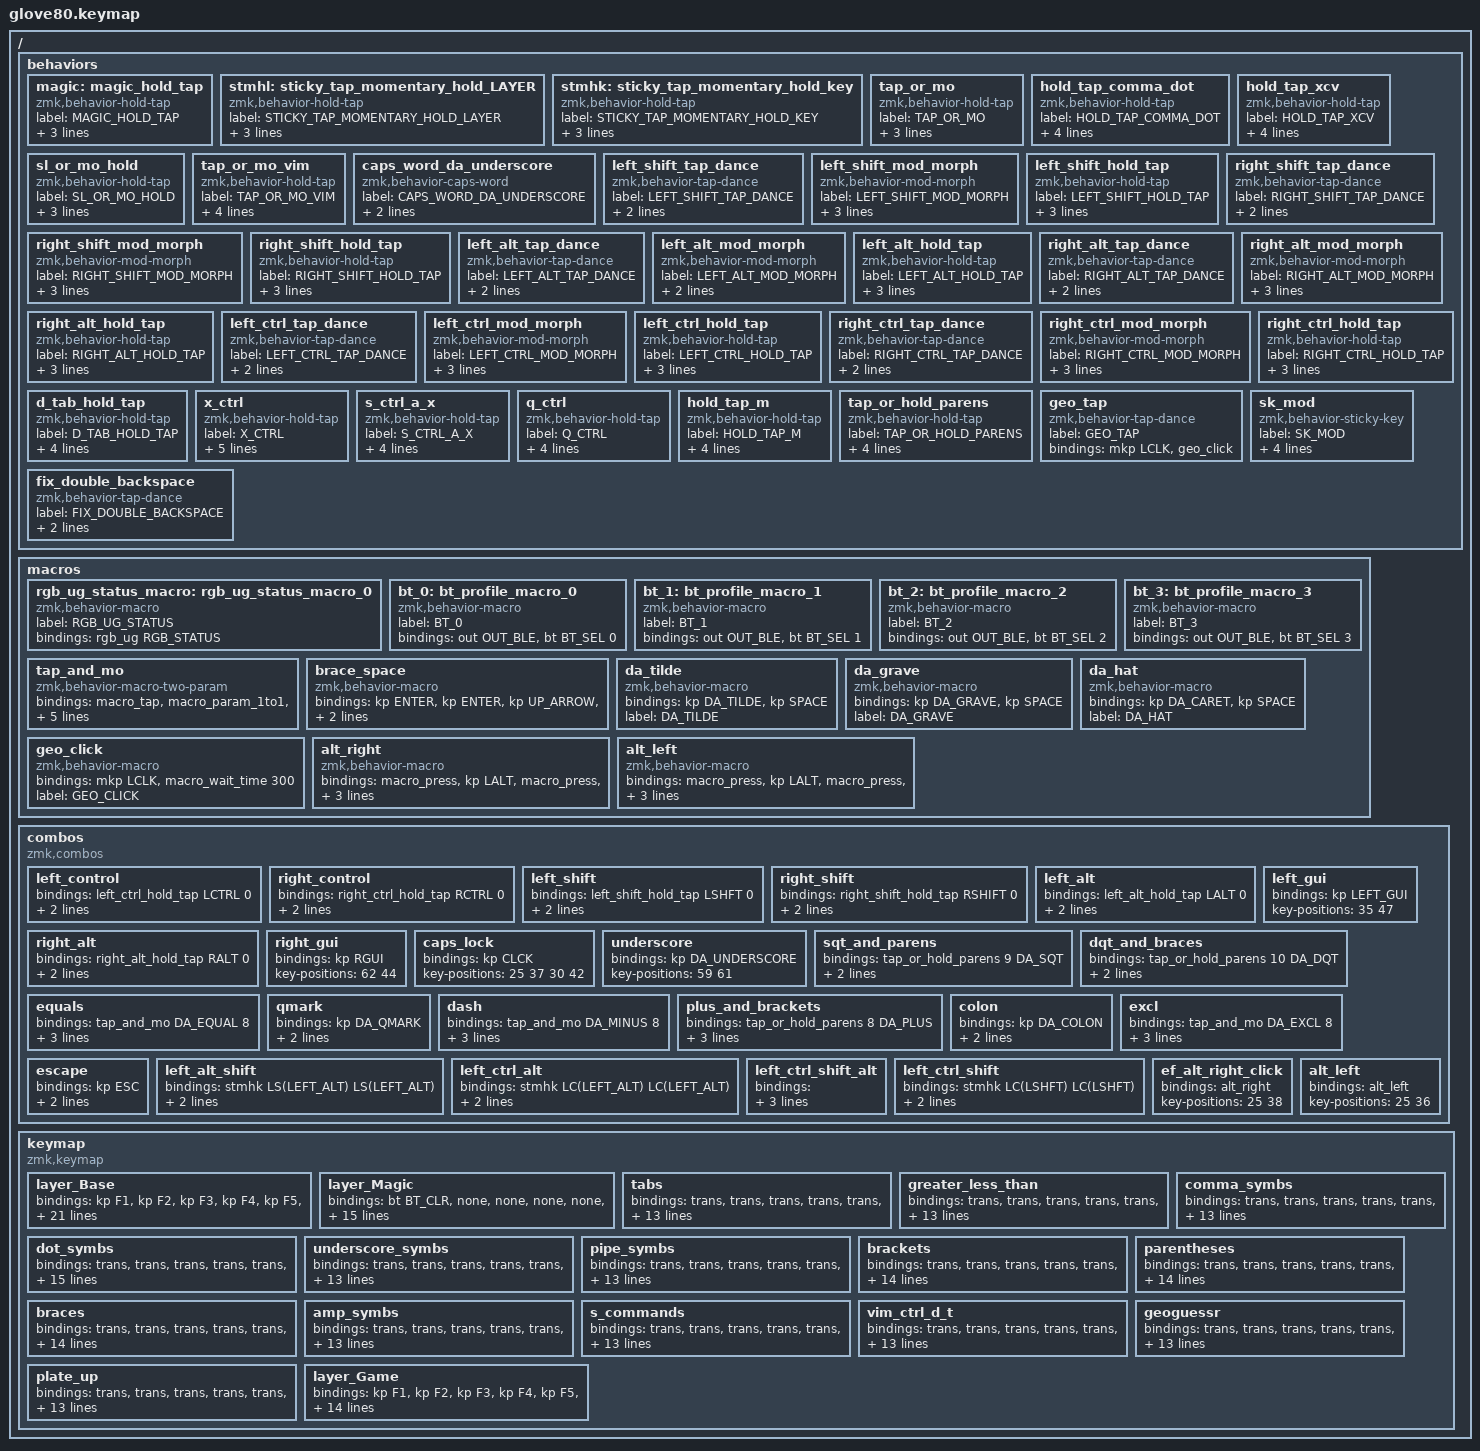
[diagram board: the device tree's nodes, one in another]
/*
 * Copyright (c) 2020 The ZMK Contributors
 * Copyright (c) 2022 Innaworks Development Limited, trading as MoErgo
 *
 * SPDX-License-Identifier: MIT
 */
/* THIS FILE WAS GENERATED BY GLOVE80 LAYOUT EDITOR
 *
 * This file was generated automatically. You may or may not want to
 * edit it directly.
 */
/* Include all behaviour includes needed by system behaviors/macros */
/* Include behaviour includes needed by key binds - automatically generated */

#include "keys_da.h"
#include <dt-bindings/zmk/mouse.h>
#include <behaviors.dtsi>
#include <dt-bindings/zmk/bt.h>
#include <dt-bindings/zmk/keys.h>
#include <dt-bindings/zmk/outputs.h>
//#include <dt-bindings/zmk/pointing.h>
#include <dt-bindings/zmk/rgb.h>

/ {
    /* Glove80 system behavior & macros */

    behaviors {
        // For the "layer" key, it'd nice to be able to use it as either a shift or a toggle.
        // Configure it as a tap dance, so the first tap (or hold) is a &mo and the second tap is a &to

        magic: magic_hold_tap {
            compatible = "zmk,behavior-hold-tap";
            label = "MAGIC_HOLD_TAP";
            #binding-cells = <2>;
            flavor = "tap-preferred";
            tapping-term-ms = <200>;
            bindings = <&mo>, <&rgb_ug_status_macro>;
        };

        stmhl: sticky_tap_momentary_hold_LAYER {
            compatible = "zmk,behavior-hold-tap";
            label = "STICKY_TAP_MOMENTARY_HOLD_LAYER";
            bindings = <&mo>, <&sl>;

            #binding-cells = <2>;
            tapping-term-ms = <400>;
            flavor = "tap-preferred";
        };

        stmhk: sticky_tap_momentary_hold_key {
            compatible = "zmk,behavior-hold-tap";
            label = "STICKY_TAP_MOMENTARY_HOLD_KEY";
            bindings = <&kp>, <&sk>;

            #binding-cells = <2>;
            tapping-term-ms = <400>;
            flavor = "hold-preferred";
        };

        tap_or_mo: tap_or_mo {
            compatible = "zmk,behavior-hold-tap";
            label = "TAP_OR_MO";
            bindings = <&mo>, <&kp>;

            #binding-cells = <2>;
            flavor = "hold-preferred";
            tapping-term-ms = <300>;
        };

        hold_tap_comma_dot: hold_tap_comma_dot {
            compatible = "zmk,behavior-hold-tap";
            label = "HOLD_TAP_COMMA_DOT";
            bindings = <&mo>, <&kp>;

            #binding-cells = <2>;
            flavor = "hold-preferred";
            tapping-term-ms = <300>;
            hold-trigger-key-positions = <61 60 42 30 59>;
        };

        hold_tap_xcv: hold_tap_xcv {
            compatible = "zmk,behavior-hold-tap";
            label = "HOLD_TAP_XCV";
            bindings = <&mo>, <&kp>;

            #binding-cells = <2>;
            flavor = "hold-preferred";
            tapping-term-ms = <300>;
            hold-trigger-key-positions = <48 50>;
        };

        sl_or_mo_hold: sl_or_mo_hold {
            compatible = "zmk,behavior-hold-tap";
            label = "SL_OR_MO_HOLD";
            bindings = <&mo>, <&sl>;

            #binding-cells = <2>;
            flavor = "hold-preferred";
            tapping-term-ms = <300>;
        };

        tap_or_mo_vim: tap_or_mo_vim {
            compatible = "zmk,behavior-hold-tap";
            label = "TAP_OR_MO_VIM";
            bindings = <&mo>, <&kp>;

            #binding-cells = <2>;
            flavor = "hold-preferred";
            tapping-term-ms = <300>;
            hold-trigger-key-positions = <36 37 38 25>;
        };

        caps_word_da_underscore: caps_word_da_underscore {
            compatible = "zmk,behavior-caps-word";
            label = "CAPS_WORD_DA_UNDERSCORE";
            #binding-cells = <0>;
            continue-list = <DA_UNDERSCORE DA_MINUS>;
            mods = <(MOD_LSFT)>;
        };

        left_shift_tap_dance: left_shift_tap_dance {
            compatible = "zmk,behavior-tap-dance";
            label = "LEFT_SHIFT_TAP_DANCE";
            #binding-cells = <0>;
            bindings = <&sk LSHFT>, <&kp LC(DA_H)>;

            tapping-term-ms = <400>;
        };

        left_shift_mod_morph: left_shift_mod_morph {
            compatible = "zmk,behavior-mod-morph";
            label = "LEFT_SHIFT_MOD_MORPH";
            bindings = <&left_shift_tap_dance>, <&caps_word_da_underscore>;

            #binding-cells = <0>;
            mods = <(MOD_RSFT)>;
        };

        left_shift_hold_tap: left_shift_hold_tap {
            compatible = "zmk,behavior-hold-tap";
            label = "LEFT_SHIFT_HOLD_TAP";
            bindings = <&kp>, <&left_shift_mod_morph>;

            #binding-cells = <2>;
            tapping-term-ms = <400>;
            quick-tap-ms = <400>;
        };

        right_shift_tap_dance: right_shift_tap_dance {
            compatible = "zmk,behavior-tap-dance";
            label = "RIGHT_SHIFT_TAP_DANCE";
            #binding-cells = <0>;
            bindings = <&sk RSHFT>, <&kp RC(DA_K)>;

            tapping-term-ms = <400>;
        };

        right_shift_mod_morph: right_shift_mod_morph {
            compatible = "zmk,behavior-mod-morph";
            label = "RIGHT_SHIFT_MOD_MORPH";
            bindings = <&right_shift_tap_dance>, <&caps_word_da_underscore>;

            #binding-cells = <0>;
            mods = <(MOD_LSFT)>;
        };

        right_shift_hold_tap: right_shift_hold_tap {
            compatible = "zmk,behavior-hold-tap";
            label = "RIGHT_SHIFT_HOLD_TAP";
            bindings = <&kp>, <&right_shift_mod_morph>;

            #binding-cells = <2>;
            tapping-term-ms = <400>;
            quick-tap-ms = <400>;
        };

        left_alt_tap_dance: left_alt_tap_dance {
            compatible = "zmk,behavior-tap-dance";
            label = "LEFT_ALT_TAP_DANCE";
            #binding-cells = <0>;
            bindings = <&sk LALT>, <&kp LEFT_ALT>;

            tapping-term-ms = <400>;
        };

        left_alt_mod_morph: left_alt_mod_morph {
            compatible = "zmk,behavior-mod-morph";
            label = "LEFT_ALT_MOD_MORPH";
            bindings = <&left_alt_tap_dance>, <&kp LA(LS(ENTER))>;

            #binding-cells = <0>;
            mods = <(MOD_RALT)>;
        };

        left_alt_hold_tap: left_alt_hold_tap {
            compatible = "zmk,behavior-hold-tap";
            label = "LEFT_ALT_HOLD_TAP";
            bindings = <&kp>, <&left_alt_mod_morph>;

            #binding-cells = <2>;
            tapping-term-ms = <400>;
            quick-tap-ms = <400>;
        };

        right_alt_tap_dance: right_alt_tap_dance {
            compatible = "zmk,behavior-tap-dance";
            label = "RIGHT_ALT_TAP_DANCE";
            #binding-cells = <0>;
            bindings = <&sk RALT>, <&kp LA(P)>;

            tapping-term-ms = <400>;
        };

        right_alt_mod_morph: right_alt_mod_morph {
            compatible = "zmk,behavior-mod-morph";
            label = "RIGHT_ALT_MOD_MORPH";
            bindings = <&right_alt_tap_dance>, <&kp LA(LS(ENTER))>;

            #binding-cells = <0>;
            mods = <(MOD_LALT)>;
        };

        right_alt_hold_tap: right_alt_hold_tap {
            compatible = "zmk,behavior-hold-tap";
            label = "RIGHT_ALT_HOLD_TAP";
            bindings = <&kp>, <&right_alt_mod_morph>;

            #binding-cells = <2>;
            tapping-term-ms = <400>;
            quick-tap-ms = <400>;
        };

        left_ctrl_tap_dance: left_ctrl_tap_dance {
            compatible = "zmk,behavior-tap-dance";
            label = "LEFT_CTRL_TAP_DANCE";
            #binding-cells = <0>;
            bindings = <&sk LCTRL>, <&kp LCTRL>;

            tapping-term-ms = <400>;
        };

        left_ctrl_mod_morph: left_ctrl_mod_morph {
            compatible = "zmk,behavior-mod-morph";
            label = "LEFT_CTRL_MOD_MORPH";
            bindings = <&left_ctrl_tap_dance>, <&kp LA(LS(ENTER))>;

            #binding-cells = <0>;
            mods = <(MOD_RCTL)>;
        };

        left_ctrl_hold_tap: left_ctrl_hold_tap {
            compatible = "zmk,behavior-hold-tap";
            label = "LEFT_CTRL_HOLD_TAP";
            bindings = <&kp>, <&left_ctrl_mod_morph>;

            #binding-cells = <2>;
            tapping-term-ms = <400>;
            quick-tap-ms = <400>;
        };

        right_ctrl_tap_dance: right_ctrl_tap_dance {
            compatible = "zmk,behavior-tap-dance";
            label = "RIGHT_CTRL_TAP_DANCE";
            #binding-cells = <0>;
            bindings = <&sk RCTRL>, <&kp LA(P)>;

            tapping-term-ms = <400>;
        };

        right_ctrl_mod_morph: right_ctrl_mod_morph {
            compatible = "zmk,behavior-mod-morph";
            label = "RIGHT_CTRL_MOD_MORPH";
            bindings = <&right_ctrl_tap_dance>, <&kp LA(LS(ENTER))>;

            #binding-cells = <0>;
            mods = <(MOD_LCTL)>;
        };

        right_ctrl_hold_tap: right_ctrl_hold_tap {
            compatible = "zmk,behavior-hold-tap";
            label = "RIGHT_CTRL_HOLD_TAP";
            bindings = <&kp>, <&right_ctrl_mod_morph>;

            #binding-cells = <2>;
            tapping-term-ms = <400>;
            quick-tap-ms = <400>;
        };

        d_tab_hold_tap: d_tab_hold_tap {
            compatible = "zmk,behavior-hold-tap";
            label = "D_TAB_HOLD_TAP";
            bindings = <&mo>, <&kp>;

            #binding-cells = <2>;
            hold-trigger-key-positions = <38 36 39>;
            tapping-term-ms = <200>;
            flavor = "tap-preferred";
        };

        x_ctrl: x_ctrl {
            compatible = "zmk,behavior-hold-tap";
            label = "X_CTRL";
            bindings = <&kp>, <&kp>;

            #binding-cells = <2>;
            tapping-term-ms = <200>;
            flavor = "tap-preferred";
            hold-trigger-key-positions = <50 47 65 49 37 38 39 51>;
        };

        s_ctrl_a_x: s_ctrl_a_x {
            compatible = "zmk,behavior-hold-tap";
            label = "S_CTRL_A_X";
            bindings = <&mo>, <&kp>;

            #binding-cells = <2>;
            hold-trigger-key-positions = <38 50>;
            tapping-term-ms = <200>;
            flavor = "tap-preferred";
        };

        q_ctrl: q_ctrl {
            compatible = "zmk,behavior-hold-tap";
            label = "Q_CTRL";
            bindings = <&kp>, <&kp>;

            #binding-cells = <2>;
            tapping-term-ms = <200>;
            flavor = "tap-preferred";
            hold-trigger-key-positions = <26 27 24 25>;
        };

        hold_tap_m: hold_tap_m {
            compatible = "zmk,behavior-hold-tap";
            label = "HOLD_TAP_M";
            bindings = <&mo>, <&kp>;

            #binding-cells = <2>;
            flavor = "tap-preferred";
            tapping-term-ms = <300>;
            hold-trigger-key-positions = <61 60 42 30 59>;
        };

        tap_or_hold_parens: tap_or_hold_parens {
            compatible = "zmk,behavior-hold-tap";
            label = "TAP_OR_HOLD_PARENS";
            bindings = <&mo>, <&kp>;

            #binding-cells = <2>;
            flavor = "hold-preferred";
            tapping-term-ms = <300>;
            hold-trigger-key-positions = <29 41 59 75>;
        };

        geo_tap: geo_tap {
            compatible = "zmk,behavior-tap-dance";
            label = "GEO_TAP";
            #binding-cells = <0>;
            bindings = <&mkp LCLK>, <&geo_click>;
        };

        fix_double_backspace: fix_double_backspace {
            compatible = "zmk,behavior-tap-dance";
            label = "FIX_DOUBLE_BACKSPACE";
            #binding-cells = <0>;
            bindings = <&kp BACKSPACE>, <&kp BACKSPACE>;

            tapping-term-ms = <75>;
        };

        sk_mod: sk_mod {
            compatible = "zmk,behavior-sticky-key";
            label = "SK_MOD";
            bindings = <&kp>;
            #binding-cells = <1>;
            release-after-ms = <500>;
            quick-release;
            ignore-modifiers;
        };
    };

    macros {
        rgb_ug_status_macro: rgb_ug_status_macro_0 {
            label = "RGB_UG_STATUS";
            compatible = "zmk,behavior-macro";
            #binding-cells = <0>;
            bindings = <&rgb_ug RGB_STATUS>;
        };

        bt_0: bt_profile_macro_0 {
            label = "BT_0";
            compatible = "zmk,behavior-macro";
            #binding-cells = <0>;
            bindings = <&out OUT_BLE &bt BT_SEL 0>;
        };

        bt_1: bt_profile_macro_1 {
            label = "BT_1";
            compatible = "zmk,behavior-macro";
            #binding-cells = <0>;
            bindings = <&out OUT_BLE &bt BT_SEL 1>;
        };

        bt_2: bt_profile_macro_2 {
            label = "BT_2";
            compatible = "zmk,behavior-macro";
            #binding-cells = <0>;
            bindings = <&out OUT_BLE &bt BT_SEL 2>;
        };

        bt_3: bt_profile_macro_3 {
            label = "BT_3";
            compatible = "zmk,behavior-macro";
            #binding-cells = <0>;
            bindings = <&out OUT_BLE &bt BT_SEL 3>;
        };

        tap_and_mo: tap_and_mo {
            compatible = "zmk,behavior-macro-two-param";
            #binding-cells = <2>;
            bindings =
                <&macro_tap>,
                <&macro_param_1to1 &kp MACRO_PLACEHOLDER>,
                <&macro_press>,
                <&macro_param_2to1 &mo MACRO_PLACEHOLDER>,
                <&macro_pause_for_release>,
                <&macro_release>,
                <&macro_param_2to1 &mo MACRO_PLACEHOLDER>;

            label = "TAP_AND_MO";
        };

        brace_space: brace_space {
            compatible = "zmk,behavior-macro";
            #binding-cells = <0>;
            bindings = <&kp ENTER &kp ENTER &kp UP_ARROW &kp TAB>;
            label = "BRACE_SPACE";
        };

        da_tilde: da_tilde {
            compatible = "zmk,behavior-macro";
            #binding-cells = <0>;
            bindings = <&kp DA_TILDE &kp SPACE>;
            label = "DA_TILDE";
        };

        da_grave: da_grave {
            compatible = "zmk,behavior-macro";
            #binding-cells = <0>;
            bindings = <&kp DA_GRAVE &kp SPACE>;
            label = "DA_GRAVE";
        };

        da_hat: da_hat {
            compatible = "zmk,behavior-macro";
            #binding-cells = <0>;
            bindings = <&kp DA_CARET &kp SPACE>;
            label = "DA_HAT";
        };

        geo_click: geo_click {
            compatible = "zmk,behavior-macro";
            #binding-cells = <0>;
            bindings = <&mkp LCLK>, <&macro_wait_time 300>;

            label = "GEO_CLICK";
        };

        alt_right: alt_right {
            compatible = "zmk,behavior-macro";
            #binding-cells = <0>;
            bindings =
                <&macro_press>,
                <&kp LALT>,
                <&macro_press>,
                <&mkp RCLK>,
                <&macro_pause_for_release>,
                <&macro_release>,
                <&kp LALT &mkp RCLK>;

            label = "ALT_RIGHT";
        };

        alt_left: alt_left {
            compatible = "zmk,behavior-macro";
            #binding-cells = <0>;
            bindings =
                <&macro_press>,
                <&kp LALT>,
                <&macro_press>,
                <&mkp LCLK>,
                <&macro_pause_for_release>,
                <&macro_release>,
                <&kp LALT &mkp LCLK>;

            label = "ALT_LEFT";
        };
    };

    combos {
        compatible = "zmk,combos";

        left_control {
            bindings = <&left_ctrl_hold_tap LCTRL 0>;
            key-positions = <24 36>;
            slow-release;
        };

        right_control {
            bindings = <&right_ctrl_hold_tap RCTRL 0>;
            key-positions = <31 43>;
            slow-release;
        };

        left_shift {
            bindings = <&left_shift_hold_tap LSHFT 0>;
            key-positions = <37 25>;
            slow-release;
        };

        right_shift {
            bindings = <&right_shift_hold_tap RSHIFT 0>;
            key-positions = <42 30>;
            slow-release;
        };

        left_alt {
            bindings = <&left_alt_hold_tap LALT 0>;
            key-positions = <38 26>;
            slow-release;
        };

        right_alt {
            bindings = <&right_alt_hold_tap RALT 0>;
            key-positions = <41 29>;
            slow-release;
        };

        left_gui {
            bindings = <&kp LEFT_GUI>;
            key-positions = <35 47>;
        };

        right_gui {
            bindings = <&kp RGUI>;
            key-positions = <62 44>;
        };

        caps_lock {
            bindings = <&kp CLCK>;
            key-positions = <25 37 30 42>;
        };

        underscore {
            bindings = <&kp DA_UNDERSCORE>;
            key-positions = <59 61>;
        };

        sqt_and_parens {
            bindings = <&tap_or_hold_parens 9 DA_SQT>;
            key-positions = <43 42>;
            require-prior-idle-ms = <50>;
        };

        dqt_and_braces {
            bindings = <&tap_or_hold_parens 10 DA_DQT>;
            key-positions = <31 30>;
            require-prior-idle-ms = <50>;
        };

        equals {
            bindings = <&tap_and_mo DA_EQUAL 8>;
            key-positions = <59 42>;
            slow-release;
            require-prior-idle-ms = <50>;
        };

        qmark {
            bindings = <&kp DA_QMARK>;
            key-positions = <30 43>;
            require-prior-idle-ms = <50>;
        };

        dash {
            bindings = <&tap_and_mo DA_MINUS 8>;
            key-positions = <59 60>;
            slow-release;
            require-prior-idle-ms = <50>;
        };

        plus_and_brackets {
            bindings = <&tap_or_hold_parens 8 DA_PLUS>;
            key-positions = <61 60>;
            slow-release;
            require-prior-idle-ms = <50>;
        };

        colon {
            bindings = <&kp DA_COLON>;
            key-positions = <37 50>;
            require-prior-idle-ms = <50>;
        };

        excl {
            bindings = <&tap_and_mo DA_EXCL 8>;
            key-positions = <30 41>;
            slow-release;
            require-prior-idle-ms = <50>;
        };

        escape {
            bindings = <&kp ESC>;
            key-positions = <41 42>;
            require-prior-idle-ms = <50>;
        };

        left_alt_shift {
            bindings = <&stmhk LS(LEFT_ALT) LS(LEFT_ALT)>;
            key-positions = <25 26>;
            slow-release;
        };

        left_ctrl_alt {
            bindings = <&stmhk LC(LEFT_ALT) LC(LEFT_ALT)>;
            key-positions = <26 24>;
            slow-release;
        };

        left_ctrl_shift_alt {
            bindings = <&stmhk LC(LS(LEFT_ALT)) LC(LS(LEFT_ALT))>;
            key-positions = <26 24 25>;
            slow-release;
        };

        left_ctrl_shift {
            bindings = <&stmhk LC(LSHFT) LC(LSHFT)>;
            key-positions = <24 25>;
            slow-release;
        };

        ef_alt_right_click {
            bindings = <&alt_right>;
            key-positions = <25 38>;
        };

        alt_left {
            bindings = <&alt_left>;
            key-positions = <25 36>;
        };
    };

    keymap {
        compatible = "zmk,keymap";

        layer_Base {
            bindings = <
&kp F1           &kp F2                    &kp F3            &kp F4               &kp F5                                                                                                                   &kp F6           &kp F7                       &kp F8                     &kp F9             &kp F10
&kp DA_ONE_HALF  &caps_word_da_underscore  &kp NUMBER_2      &kp N3               &kp N4   &kp N5                                                                                                  &kp N6  &kp N7           &kp N8                       &kp N9                     &kp DA_MINUS       &kp DA_ACUTE
&kp F11          &kp NUMBER_1              &kp W             &kp E                &kp R    &kp T                                                                                                   &kp Y   &kp U            &kp I                        &kp O                      &kp N0             &kp DA_A_RING
&kp ESCAPE       &q_ctrl LCTRL DA_Q        &s_ctrl_a_x 12 S  &d_tab_hold_tap 2 D  &kp F    &kp G                                                                                                   &kp H   &kp J            &kp K                        &kp L                      &kp P              &kp DA_O_SLASH
&kp TAB          &kp A                     &x_ctrl LCTRL X   &hold_tap_xcv 3 C    &kp V    &kp B   &sk_mod LEFT_ALT  &kp DELETE  &to 14         &kp RIGHT_ALT  &sk_mod RCTRL  &sk_mod RIGHT_SHIFT  &kp N   &hold_tap_m 8 M  &hold_tap_comma_dot 4 COMMA  &hold_tap_comma_dot 5 DOT  &mt RCTRL DA_SEMI  &kp DA_AE
&magic 1 0       &kp Z                     &kp DA_COLON      &kp HOME             &kp END          &kp SPACE         &kp ENTER   &kp LG(SPACE)  &kp LGUI       &kp DELETE     &kp BACKSPACE                &kp LEFT         &kp DOWN                     &kp UP                     &kp RIGHT          &kp F12
            >;
        };

        layer_Magic {
            bindings = <
&bt BT_CLR   &none            &none            &none            &none                                                                                     &none  &none  &none  &none  &bt BT_CLR_ALL
&none        &none            &none            &none            &none            &none                                                             &none  &none  &none  &none  &none  &none
&none        &rgb_ug RGB_SPI  &rgb_ug RGB_SAI  &rgb_ug RGB_HUI  &rgb_ug RGB_BRI  &rgb_ug RGB_TOG                                                   &none  &none  &none  &none  &none  &none
&bootloader  &rgb_ug RGB_SPD  &rgb_ug RGB_SAD  &rgb_ug RGB_HUD  &rgb_ug RGB_BRD  &rgb_ug RGB_EFF                                                   &none  &none  &none  &none  &none  &bootloader
&sys_reset   &none            &none            &none            &none            &none            &bt_2  &bt_3  &none         &none  &none  &none  &none  &none  &none  &none  &none  &sys_reset
&none        &none            &none            &none            &none                             &bt_0  &bt_1  &out OUT_USB  &none  &none  &none         &none  &none  &none  &none  &none
            >;
        };

        tabs {
            bindings = <
&trans  &trans  &trans       &trans  &trans                                                                      &trans  &trans  &trans  &trans  &trans
&trans  &trans  &trans       &trans  &trans   &trans                                                     &trans  &trans  &trans  &trans  &trans  &trans
&trans  &trans  &trans       &trans  &trans   &trans                                                     &trans  &trans  &trans  &trans  &trans  &trans
&trans  &trans  &kp LS(TAB)  &trans  &kp TAB  &kp LC(O)                                                  &trans  &trans  &trans  &trans  &trans  &trans
&trans  &trans  &trans       &trans  &trans   &trans     &trans  &trans  &trans  &trans  &trans  &trans  &trans  &trans  &trans  &trans  &trans  &trans
&trans  &trans  &trans       &trans  &trans              &trans  &trans  &trans  &trans  &trans  &trans          &trans  &trans  &trans  &trans  &trans
            >;
        };

        greater_less_than {
            bindings = <
&trans  &trans  &trans     &trans  &trans                                                                     &trans  &trans  &trans  &trans  &trans
&trans  &trans  &trans     &trans  &trans     &trans                                                  &trans  &trans  &trans  &trans  &trans  &trans
&trans  &trans  &trans     &trans  &trans     &trans                                                  &trans  &trans  &trans  &trans  &trans  &trans
&trans  &trans  &trans     &trans  &trans     &trans                                                  &trans  &trans  &trans  &trans  &trans  &trans
&trans  &trans  &kp DA_LT  &trans  &kp DA_GT  &trans  &trans  &trans  &trans  &trans  &trans  &trans  &trans  &trans  &trans  &trans  &trans  &trans
&trans  &trans  &trans     &trans  &trans             &trans  &trans  &trans  &trans  &trans  &trans          &trans  &trans  &trans  &trans  &trans
            >;
        };

        comma_symbs {
            bindings = <
&trans  &trans  &trans  &trans  &trans                                                                  &trans        &trans  &trans       &trans  &trans
&trans  &trans  &trans  &trans  &trans  &trans                                                  &trans  &trans        &trans  &trans       &trans  &trans
&trans  &trans  &trans  &trans  &trans  &trans                                                  &trans  &trans        &trans  &trans       &trans  &trans
&trans  &trans  &trans  &trans  &trans  &trans                                                  &trans  &trans        &trans  &trans       &trans  &trans
&trans  &trans  &trans  &trans  &trans  &trans  &trans  &trans  &trans  &trans  &trans  &trans  &trans  &kp DA_MINUS  &trans  &kp DA_FSLH  &trans  &trans
&trans  &trans  &trans  &trans  &trans          &trans  &trans  &trans  &trans  &trans  &trans          &trans        &trans  &trans       &trans  &trans
            >;
        };

        dot_symbs {
            bindings = <
&trans  &trans  &trans  &trans  &trans                                                                  &trans                      &trans                 &trans  &trans  &trans
&trans  &trans  &trans  &trans  &trans  &trans                                                  &trans  &trans                      &trans                 &trans  &trans  &trans
&trans  &trans  &trans  &trans  &trans  &trans                                                  &trans  &trans                      &tap_or_mo 11 DA_AMPS  &trans  &trans  &trans
&trans  &trans  &trans  &trans  &trans  &trans                                                  &trans  &trans                      &tap_or_mo 7 DA_PIPE   &trans  &trans  &trans
&trans  &trans  &trans  &trans  &trans  &trans  &trans  &trans  &trans  &trans  &trans  &trans  &trans  &tap_or_mo 6 DA_UNDERSCORE  &tap_or_mo 8 DA_BSLH   &trans  &trans  &trans
&trans  &trans  &trans  &trans  &trans          &trans  &trans  &trans  &trans  &trans  &trans          &trans                      &trans                 &trans  &trans  &trans
            >;
        };

        underscore_symbs {
            bindings = <
&trans  &trans  &trans  &trans  &trans                                                                  &trans  &trans     &trans  &trans  &trans
&trans  &trans  &trans  &trans  &trans  &trans                                                  &trans  &trans  &trans     &trans  &trans  &trans
&trans  &trans  &trans  &trans  &trans  &trans                                                  &trans  &trans  &trans     &trans  &trans  &trans
&trans  &trans  &trans  &trans  &trans  &trans                                                  &trans  &trans  &kp DA_AT  &trans  &trans  &trans
&trans  &trans  &trans  &trans  &trans  &trans  &trans  &trans  &trans  &trans  &trans  &trans  &trans  &trans  &da_hat    &trans  &trans  &trans
&trans  &trans  &trans  &trans  &trans          &trans  &trans  &trans  &trans  &trans  &trans          &trans  &trans     &trans  &trans  &trans
            >;
        };

        pipe_symbs {
            bindings = <
&trans  &trans  &trans  &trans  &trans                                                                  &trans           &trans  &trans  &trans  &trans
&trans  &trans  &trans  &trans  &trans  &trans                                                  &trans  &trans           &trans  &trans  &trans  &trans
&trans  &trans  &trans  &trans  &trans  &trans                                                  &trans  &da_grave        &trans  &trans  &trans  &trans
&trans  &trans  &trans  &trans  &trans  &trans                                                  &trans  &kp DA_HASH      &trans  &trans  &trans  &trans
&trans  &trans  &trans  &trans  &trans  &trans  &trans  &trans  &trans  &trans  &trans  &trans  &trans  &kp DA_ASTERISK  &trans  &trans  &trans  &trans
&trans  &trans  &trans  &trans  &trans          &trans  &trans  &trans  &trans  &trans  &trans          &trans           &trans  &trans  &trans  &trans
            >;
        };

        brackets {
            bindings = <
&trans  &trans  &trans  &trans  &trans                                                                  &trans               &trans        &trans       &trans  &trans
&trans  &trans  &trans  &trans  &trans  &trans                                                  &trans  &trans               &trans        &trans       &trans  &trans
&trans  &trans  &trans  &trans  &trans  &trans                                                  &trans  &brace_space         &kp DA_EXCL   &trans       &trans  &trans
&trans  &trans  &trans  &trans  &trans  &trans                                                  &trans  &kp DA_LEFT_BRACKET  &kp DA_EQUAL  &trans       &trans  &trans
&trans  &trans  &trans  &trans  &trans  &trans  &trans  &trans  &trans  &trans  &trans  &trans  &trans  &kp DA_RBKT          &kp DA_MINUS  &kp DA_PLUS  &trans  &trans
&trans  &trans  &trans  &trans  &trans          &trans  &trans  &trans  &trans  &trans  &trans          &kp LEFT             &trans        &trans       &trans  &trans
            >;
        };

        parentheses {
            bindings = <
&trans  &trans  &trans  &trans  &trans                                                                  &trans                   &trans  &trans  &trans  &trans
&trans  &trans  &trans  &trans  &trans  &trans                                                  &trans  &trans                   &trans  &trans  &trans  &trans
&trans  &trans  &trans  &trans  &trans  &trans                                                  &trans  &brace_space             &trans  &trans  &trans  &trans
&trans  &trans  &trans  &trans  &trans  &trans                                                  &trans  &kp DA_LEFT_PARENTHESIS  &trans  &trans  &trans  &trans
&trans  &trans  &trans  &trans  &trans  &trans  &trans  &trans  &trans  &trans  &trans  &trans  &trans  &kp DA_RPAR              &trans  &trans  &trans  &trans
&trans  &trans  &trans  &trans  &trans          &trans  &trans  &trans  &trans  &trans  &trans          &kp LEFT                 &trans  &trans  &trans  &trans
            >;
        };

        braces {
            bindings = <
&trans  &trans  &trans  &trans  &trans                                                                  &trans             &trans  &trans  &trans  &trans
&trans  &trans  &trans  &trans  &trans  &trans                                                  &trans  &trans             &trans  &trans  &trans  &trans
&trans  &trans  &trans  &trans  &trans  &trans                                                  &trans  &kp DA_LEFT_BRACE  &trans  &trans  &trans  &trans
&trans  &trans  &trans  &trans  &trans  &trans                                                  &trans  &kp DA_RBRC        &trans  &trans  &trans  &trans
&trans  &trans  &trans  &trans  &trans  &trans  &trans  &trans  &trans  &trans  &trans  &trans  &trans  &kp LEFT           &trans  &trans  &trans  &trans
&trans  &trans  &trans  &trans  &trans          &trans  &trans  &trans  &trans  &trans  &trans          &brace_space       &trans  &trans  &trans  &trans
            >;
        };

        amp_symbs {
            bindings = <
&trans  &trans  &trans  &trans  &trans                                                                  &trans          &trans  &trans  &trans  &trans
&trans  &trans  &trans  &trans  &trans  &trans                                                  &trans  &trans          &trans  &trans  &trans  &trans
&trans  &trans  &trans  &trans  &trans  &trans                                                  &trans  &da_tilde       &trans  &trans  &trans  &trans
&trans  &trans  &trans  &trans  &trans  &trans                                                  &trans  &kp DA_PERCENT  &trans  &trans  &trans  &trans
&trans  &trans  &trans  &trans  &trans  &trans  &trans  &trans  &trans  &trans  &trans  &trans  &trans  &kp DA_DOLLAR   &trans  &trans  &trans  &trans
&trans  &trans  &trans  &trans  &trans          &trans  &trans  &trans  &trans  &trans  &trans          &trans          &trans  &trans  &trans  &trans
            >;
        };

        s_commands {
            bindings = <
&trans  &trans  &trans  &trans  &trans                                                                            &trans  &trans  &trans  &trans  &trans
&trans  &trans  &trans  &trans  &trans     &trans                                                         &trans  &trans  &trans  &trans  &trans  &trans
&trans  &trans  &trans  &trans  &trans     &kp LS(LC(G))                                                  &trans  &trans  &trans  &trans  &trans  &trans
&trans  &trans  &trans  &trans  &kp LC(A)  &kp LC(G)                                                      &trans  &trans  &trans  &trans  &trans  &trans
&trans  &trans  &trans  &trans  &kp LC(X)  &trans         &trans  &trans  &trans  &trans  &trans  &trans  &trans  &trans  &trans  &trans  &trans  &trans
&trans  &trans  &trans  &trans  &trans                    &trans  &trans  &trans  &trans  &trans  &trans          &trans  &trans  &trans  &trans  &trans
            >;
        };

        vim_ctrl_d_t {
            bindings = <
&trans  &trans  &trans  &trans  &trans                                                                     &trans  &trans  &trans  &trans  &trans
&trans  &trans  &trans  &trans  &trans  &trans                                                     &trans  &trans  &trans  &trans  &trans  &trans
&trans  &trans  &trans  &trans  &trans  &kp LC(T)                                                  &trans  &trans  &trans  &trans  &trans  &trans
&trans  &trans  &trans  &trans  &trans  &kp LC(D)                                                  &trans  &trans  &trans  &trans  &trans  &trans
&trans  &trans  &trans  &trans  &trans  &trans     &trans  &trans  &trans  &trans  &trans  &trans  &trans  &trans  &trans  &trans  &trans  &trans
&trans  &trans  &trans  &trans  &trans             &trans  &trans  &trans  &trans  &trans  &trans          &trans  &trans  &trans  &trans  &trans
            >;
        };

        geoguessr {
            bindings = <
&trans  &trans  &trans  &trans     &trans                                                                  &trans  &trans  &trans  &trans  &trans
&trans  &trans  &trans  &trans     &trans  &trans                                                  &trans  &trans  &trans  &trans  &trans  &trans
&trans  &trans  &trans  &trans     &trans  &trans                                                  &trans  &trans  &trans  &trans  &trans  &trans
&trans  &trans  &trans  &kp D      &trans  &trans                                                  &trans  &trans  &trans  &trans  &trans  &trans
&trans  &trans  &kp X   &mkp LCLK  &kp V   &trans  &trans  &trans  &to 15  &trans  &trans  &trans  &trans  &trans  &trans  &trans  &trans  &trans
&trans  &trans  &trans  &trans     &trans          &trans  &trans  &trans  &trans  &trans  &trans          &trans  &trans  &trans  &trans  &trans
            >;
        };

        plate_up {
            bindings = <
&trans  &trans  &trans          &trans    &trans                                                                     &trans  &trans  &trans  &trans  &trans
&trans  &trans  &trans          &trans    &trans     &trans                                                  &trans  &trans  &trans  &trans  &trans  &trans
&trans  &trans  &trans          &kp UP    &trans     &trans                                                  &trans  &trans  &trans  &trans  &trans  &trans
&trans  &trans  &kp LEFT_ARROW  &kp DOWN  &kp RIGHT  &trans                                                  &trans  &kp P   &kp O   &trans  &trans  &trans
&trans  &trans  &trans          &trans    &trans     &trans  &trans  &trans  &to 16  &trans  &trans  &trans  &trans  &trans  &trans  &trans  &trans  &trans
&trans  &trans  &trans          &trans    &trans             &trans  &trans  &trans  &trans  &trans  &trans          &trans  &trans  &trans  &trans  &trans
            >;
        };

        layer_Game {
            bindings = <
&kp F1        &kp F2     &kp F3  &kp F4  &kp F5                                                                       &trans  &trans  &trans  &trans  &trans
&kp N8        &kp N5     &kp N1  &kp N2  &kp N3  &kp N4                                                       &trans  &trans  &trans  &trans  &trans  &trans
&kp N7        &kp ESC    &kp Q   &kp W   &kp E   &kp R                                                        &trans  &trans  &trans  &trans  &trans  &trans
&kp N6        &kp TAB    &kp A   &kp S   &kp D   &kp F                                                        &trans  &trans  &trans  &trans  &trans  &trans
&kp KP_PLUS   &kp LSHFT  &kp Z   &kp X   &kp C   &kp V   &kp LALT   &kp H      &to 0  &trans  &trans  &trans  &trans  &trans  &trans  &trans  &trans  &trans
&kp KP_SLASH  &kp LCTRL  &kp T   &kp G   &kp B           &kp SPACE  &kp ENTER  &kp Y  &trans  &trans  &trans          &trans  &trans  &trans  &trans  &trans
            >;
        };
    };
};
